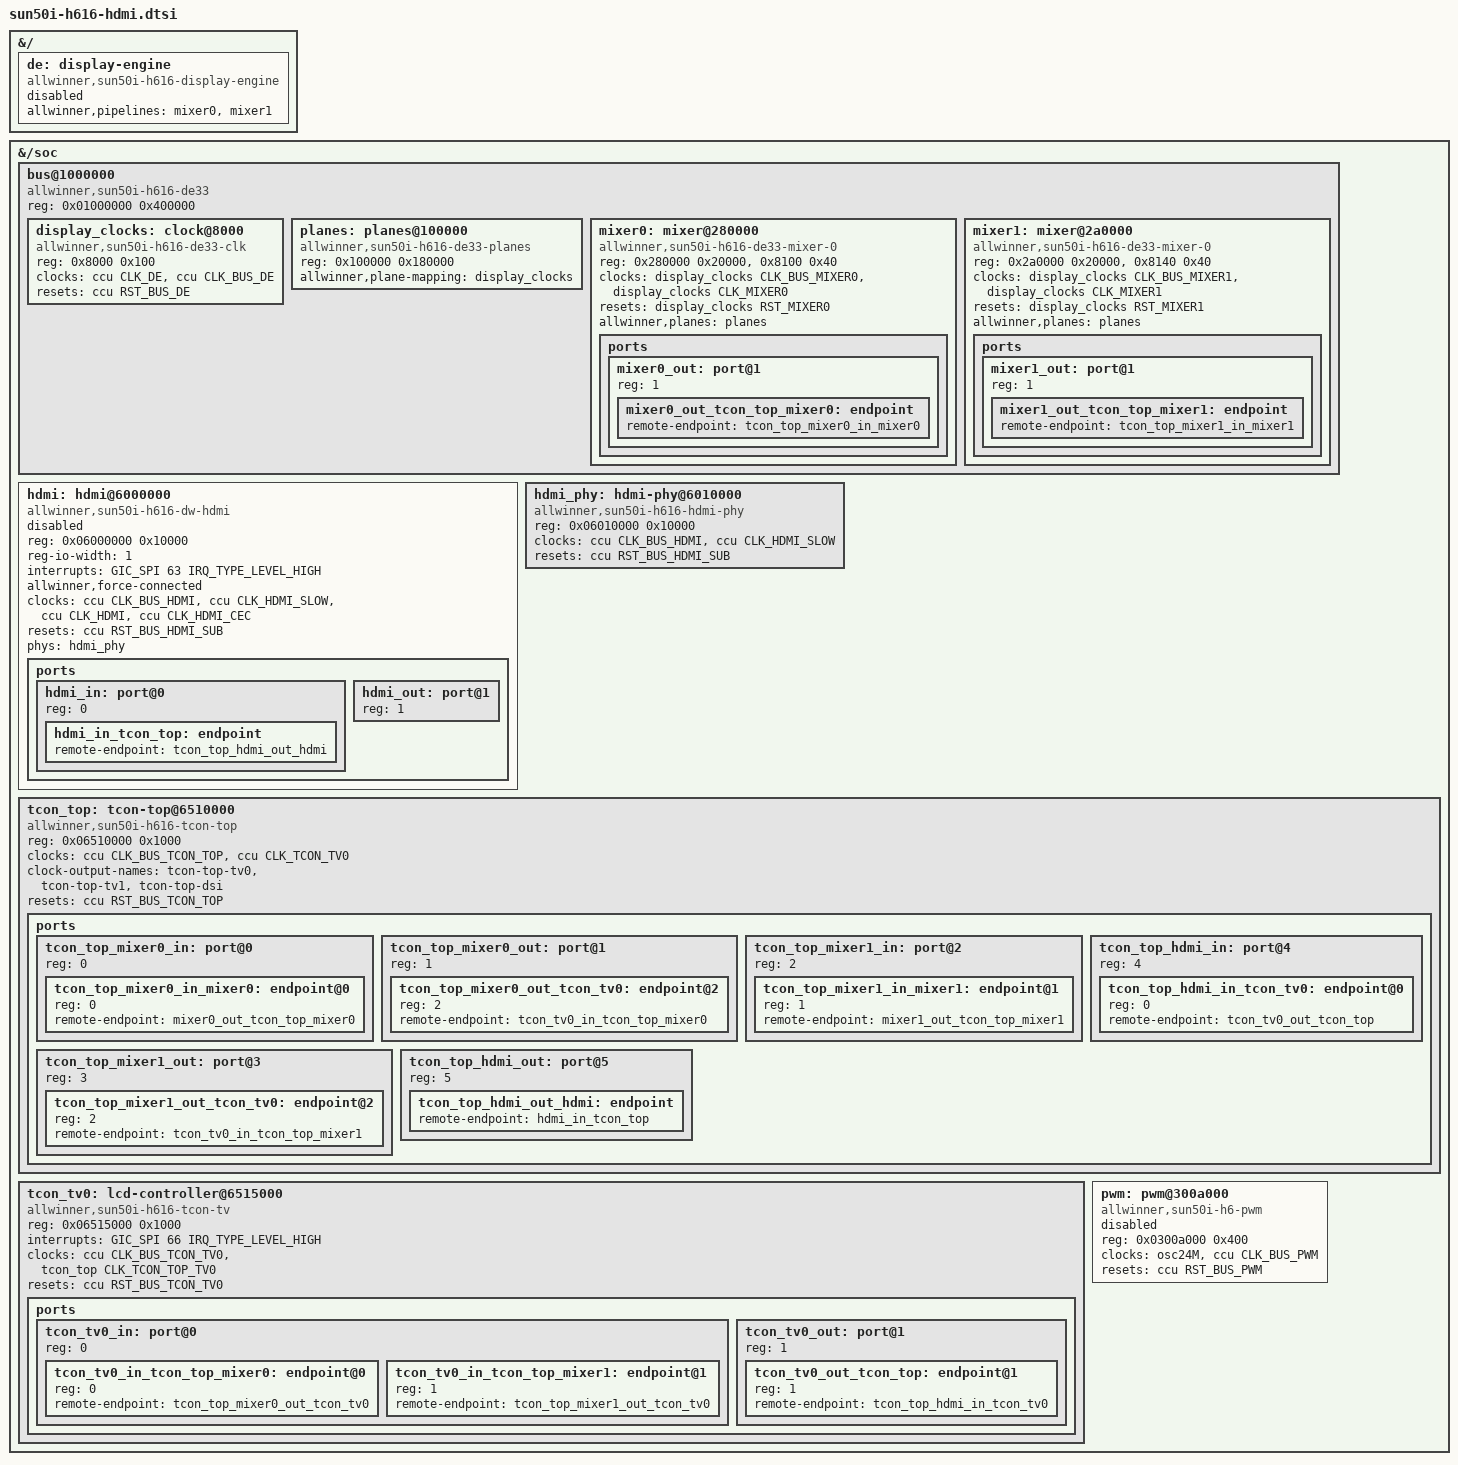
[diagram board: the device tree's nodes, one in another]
// SPDX-License-Identifier: (GPL-2.0+ OR MIT)

#include <dt-bindings/interrupt-controller/arm-gic.h>
#include <dt-bindings/clock/sun50i-h616-ccu.h>
#include <dt-bindings/reset/sun50i-h616-ccu.h>
#include <dt-bindings/clock/sun8i-de2.h>
#include <dt-bindings/reset/sun8i-de2.h>
#include <dt-bindings/clock/sun8i-tcon-top.h>

&{/} {
	de: display-engine {
		compatible = "allwinner,sun50i-h616-display-engine";
		allwinner,pipelines = <&mixer0>, <&mixer1>;
		status = "disabled";
	};
};

&{/soc} {
	bus@1000000 {
		compatible = "allwinner,sun50i-h616-de33",
			     "allwinner,sun50i-a64-de2";
		reg = <0x01000000 0x400000>;
		#address-cells = <1>;
		#size-cells = <1>;
		ranges = <0 0x01000000 0x400000>;

		display_clocks: clock@8000 {
			compatible = "allwinner,sun50i-h616-de33-clk",
				     "allwinner,sun50i-h6-de3-clk";
			reg = <0x8000 0x100>;
			clocks = <&ccu CLK_DE>, <&ccu CLK_BUS_DE>;
			clock-names = "mod", "bus";
			resets = <&ccu RST_BUS_DE>;
			#clock-cells = <1>;
			#reset-cells = <1>;
		};

		planes: planes@100000 {
			compatible = "allwinner,sun50i-h616-de33-planes";
			reg = <0x100000 0x180000>;
			allwinner,plane-mapping = <&display_clocks>;
		};

		mixer0: mixer@280000 {
			compatible = "allwinner,sun50i-h616-de33-mixer-0",
				     "allwinner,sun50i-h6-de3-mixer-0";
			reg = <0x280000 0x20000>, <0x8100 0x40>;
			reg-names = "display", "top";
			clocks = <&display_clocks CLK_BUS_MIXER0>,
				 <&display_clocks CLK_MIXER0>;
			clock-names = "bus", "mod";
			resets = <&display_clocks RST_MIXER0>;
			allwinner,planes = <&planes>;

			ports {
				#address-cells = <1>;
				#size-cells = <0>;

				mixer0_out: port@1 {
					reg = <1>;

					mixer0_out_tcon_top_mixer0: endpoint {
						remote-endpoint = <&tcon_top_mixer0_in_mixer0>;
					};
				};
			};
		};

		mixer1: mixer@2a0000 {
			compatible = "allwinner,sun50i-h616-de33-mixer-0",
				     "allwinner,sun50i-h6-de3-mixer-0";
			reg = <0x2a0000 0x20000>, <0x8140 0x40>;
			reg-names = "display", "top";
			clocks = <&display_clocks CLK_BUS_MIXER1>,
				 <&display_clocks CLK_MIXER1>;
			clock-names = "bus", "mod";
			resets = <&display_clocks RST_MIXER1>;
			allwinner,planes = <&planes>;

			ports {
				#address-cells = <1>;
				#size-cells = <0>;

				mixer1_out: port@1 {
					reg = <1>;

					mixer1_out_tcon_top_mixer1: endpoint {
						remote-endpoint = <&tcon_top_mixer1_in_mixer1>;
					};
				};
			};
		};
	};

	hdmi: hdmi@6000000 {
		compatible = "allwinner,sun50i-h616-dw-hdmi",
			     "allwinner,sun50i-h6-dw-hdmi";
		reg = <0x06000000 0x10000>;
		reg-io-width = <1>;
		interrupts = <GIC_SPI 63 IRQ_TYPE_LEVEL_HIGH>;
		allwinner,force-connected;
		clocks = <&ccu CLK_BUS_HDMI>, <&ccu CLK_HDMI_SLOW>,
			 <&ccu CLK_HDMI>, <&ccu CLK_HDMI_CEC>;
		clock-names = "iahb", "isfr", "tmds", "cec";
		resets = <&ccu RST_BUS_HDMI_SUB>;
		reset-names = "ctrl";
		phys = <&hdmi_phy>;
		phy-names = "phy";
		status = "disabled";

		ports {
			#address-cells = <1>;
			#size-cells = <0>;

			hdmi_in: port@0 {
				reg = <0>;

				hdmi_in_tcon_top: endpoint {
					remote-endpoint = <&tcon_top_hdmi_out_hdmi>;
				};
			};

			hdmi_out: port@1 {
				reg = <1>;
			};
		};
	};

	hdmi_phy: hdmi-phy@6010000 {
		compatible = "allwinner,sun50i-h616-hdmi-phy",
			     "allwinner,sun50i-h6-hdmi-phy";
		reg = <0x06010000 0x10000>;
		clocks = <&ccu CLK_BUS_HDMI>, <&ccu CLK_HDMI_SLOW>;
		clock-names = "bus", "mod";
		resets = <&ccu RST_BUS_HDMI_SUB>;
		reset-names = "phy";
		#phy-cells = <0>;
	};

	tcon_top: tcon-top@6510000 {
		compatible = "allwinner,sun50i-h616-tcon-top",
			     "allwinner,sun50i-h6-tcon-top";
		reg = <0x06510000 0x1000>;
		clocks = <&ccu CLK_BUS_TCON_TOP>,
			 <&ccu CLK_TCON_TV0>;
		clock-names = "bus", "tcon-tv0";
		clock-output-names = "tcon-top-tv0", "tcon-top-tv1", "tcon-top-dsi";
		resets = <&ccu RST_BUS_TCON_TOP>;
		#clock-cells = <1>;

		ports {
			#address-cells = <1>;
			#size-cells = <0>;

			tcon_top_mixer0_in: port@0 {
				#address-cells = <1>;
				#size-cells = <0>;
				reg = <0>;

				tcon_top_mixer0_in_mixer0: endpoint@0 {
					reg = <0>;
					remote-endpoint = <&mixer0_out_tcon_top_mixer0>;
				};
			};

			tcon_top_mixer0_out: port@1 {
				#address-cells = <1>;
				#size-cells = <0>;
				reg = <1>;

				tcon_top_mixer0_out_tcon_tv0: endpoint@2 {
					reg = <2>;
					remote-endpoint = <&tcon_tv0_in_tcon_top_mixer0>;
				};
			};

			tcon_top_mixer1_in: port@2 {
				#address-cells = <1>;
				#size-cells = <0>;
				reg = <2>;

				tcon_top_mixer1_in_mixer1: endpoint@1 {
					reg = <1>;
					remote-endpoint = <&mixer1_out_tcon_top_mixer1>;
				};
			};

			tcon_top_mixer1_out: port@3 {
				#address-cells = <1>;
				#size-cells = <0>;
				reg = <3>;

				tcon_top_mixer1_out_tcon_tv0: endpoint@2 {
					reg = <2>;
					remote-endpoint = <&tcon_tv0_in_tcon_top_mixer1>;
				};
			};

			tcon_top_hdmi_in: port@4 {
				#address-cells = <1>;
				#size-cells = <0>;
				reg = <4>;

				tcon_top_hdmi_in_tcon_tv0: endpoint@0 {
					reg = <0>;
					remote-endpoint = <&tcon_tv0_out_tcon_top>;
				};
			};

			tcon_top_hdmi_out: port@5 {
				reg = <5>;

				tcon_top_hdmi_out_hdmi: endpoint {
					remote-endpoint = <&hdmi_in_tcon_top>;
				};
			};
		};
	};

	tcon_tv0: lcd-controller@6515000 {
		compatible = "allwinner,sun50i-h616-tcon-tv",
			     "allwinner,sun50i-h6-tcon-tv",
			     "allwinner,sun8i-r40-tcon-tv";
		reg = <0x06515000 0x1000>;
		interrupts = <GIC_SPI 66 IRQ_TYPE_LEVEL_HIGH>;
		clocks = <&ccu CLK_BUS_TCON_TV0>,
			 <&tcon_top CLK_TCON_TOP_TV0>;
		clock-names = "ahb", "tcon-ch1";
		resets = <&ccu RST_BUS_TCON_TV0>;
		reset-names = "lcd";

		ports {
			#address-cells = <1>;
			#size-cells = <0>;

			tcon_tv0_in: port@0 {
				#address-cells = <1>;
				#size-cells = <0>;
				reg = <0>;

				tcon_tv0_in_tcon_top_mixer0: endpoint@0 {
					reg = <0>;
					remote-endpoint = <&tcon_top_mixer0_out_tcon_tv0>;
				};

				tcon_tv0_in_tcon_top_mixer1: endpoint@1 {
					reg = <1>;
					remote-endpoint = <&tcon_top_mixer1_out_tcon_tv0>;
				};
			};

			tcon_tv0_out: port@1 {
				#address-cells = <1>;
				#size-cells = <0>;
				reg = <1>;

				tcon_tv0_out_tcon_top: endpoint@1 {
					reg = <1>;
					remote-endpoint = <&tcon_top_hdmi_in_tcon_tv0>;
				};
			};
		};
	};

	pwm: pwm@300a000 {
		compatible = "allwinner,sun50i-h6-pwm";
		reg = <0x0300a000 0x400>;
		clocks = <&osc24M>, <&ccu CLK_BUS_PWM>;
		clock-names = "mod", "bus";
		resets = <&ccu RST_BUS_PWM>;
		#pwm-cells = <3>;
		status = "disabled";
	};
};

